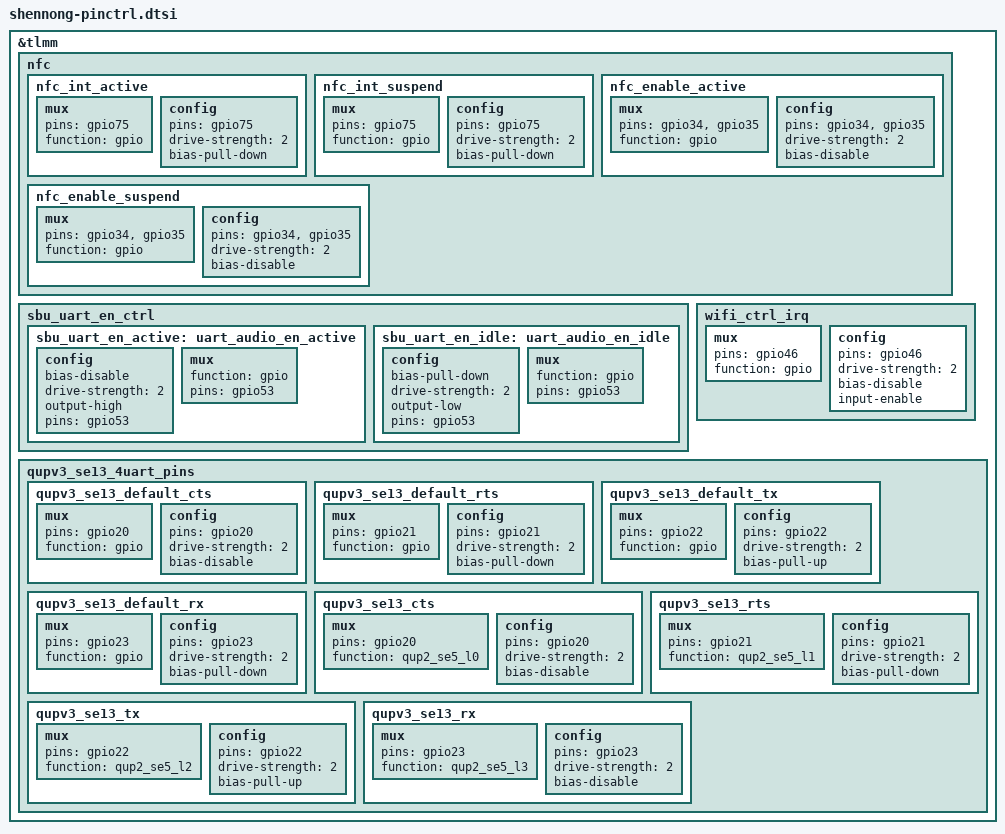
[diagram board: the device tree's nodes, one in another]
/*for shennong pinctrl */
&tlmm {
	nfc {
		nfc_int_active: nfc_int_active {
			/* active state */
			mux {
				/* NFC Read Interrupt */
				pins = "gpio75";
				function = "gpio";
			};

			config {
				pins = "gpio75";
				drive-strength = <2>; /* 2 MA */
				bias-pull-down;
			};
		};

		nfc_int_suspend: nfc_int_suspend {
			/* sleep state */
			mux {
				/* NFC Read Interrupt */
				pins = "gpio75";
				function = "gpio";
			};

			config {
				pins = "gpio75";
				drive-strength = <2>; /* 2 MA */
				bias-pull-down;
			};
		};

		nfc_enable_active: nfc_enable_active {
			mux {
				/* Enable, and Clock request gpios */
				pins = "gpio34", "gpio35";
				function = "gpio";
			};

			config {
				pins = "gpio34", "gpio35";
				drive-strength = <2>; /* 2 MA */
				bias-disable;
			};
		};

		nfc_enable_suspend: nfc_enable_suspend {
			mux {
				pins = "gpio34", "gpio35";
				function = "gpio";
			};

			config {
				pins = "gpio34", "gpio35";
				drive-strength = <2>; /* 2 MA */
				bias-disable;
			};
		};
	}; //nfc

	sbu_uart_en_ctrl {
		sbu_uart_en_active: uart_audio_en_active {
			config {
				bias-disable;
				drive-strength = <2>; /* 2 MA */
				output-high;
				pins = "gpio53";
			};

			mux {
				function = "gpio";
				pins = "gpio53";
			};
		};

		sbu_uart_en_idle: uart_audio_en_idle {
			config {
				bias-pull-down;
				drive-strength = <2>; /* 2 MA */
				output-low;
				pins = "gpio53";
			};

			mux {
				function = "gpio";
				pins = "gpio53";
			};
		};
	};

	wifi_ctrl_irq: wifi_ctrl_irq {
		mux {
			pins = "gpio46";
			function = "gpio";
		};

		config {
			pins = "gpio46";
			drive-strength = <2>;   /* 2 mA */
			bias-disable;
			input-enable;
		};
	}; //wifi

	qupv3_se13_4uart_pins: qupv3_se13_4uart_pins {
		qupv3_se13_default_cts: qupv3_se13_default_cts {
			mux {
				pins = "gpio20";
				function = "gpio";
			};

			config {
				pins = "gpio20";
				drive-strength = <2>;
				bias-disable;
			};
		};

		qupv3_se13_default_rts: qupv3_se13_default_rts {
			mux {
				pins = "gpio21";
				function = "gpio";
			};

			config {
				pins = "gpio21";
				drive-strength = <2>;
				bias-pull-down;
			};
		};

		qupv3_se13_default_tx: qupv3_se13_default_tx {
			mux {
				pins = "gpio22";
				function = "gpio";
			};

			config {
				pins = "gpio22";
				drive-strength = <2>;
				bias-pull-up;
			};
		};

		qupv3_se13_default_rx: qupv3_se13_default_rx {
			mux {
				pins = "gpio23";
				function = "gpio";
			};

			config {
				pins = "gpio23";
				drive-strength = <2>;
				bias-pull-down;
			};
		};

		qupv3_se13_cts: qupv3_se13_cts {
			mux {
				pins = "gpio20";
				function = "qup2_se5_l0";
			};

			config {
				pins = "gpio20";
				drive-strength = <2>;
				bias-disable;
			};
		};

		qupv3_se13_rts: qupv3_se13_rts {
			mux {
				pins = "gpio21";
				function = "qup2_se5_l1";
			};

			config {
				pins = "gpio21";
				drive-strength = <2>;
				bias-pull-down;
			};
		};

		qupv3_se13_tx: qupv3_se13_tx {
			mux {
				pins = "gpio22";
				function = "qup2_se5_l2";
			};

			config {
				pins = "gpio22";
				drive-strength = <2>;
				bias-pull-up;
			};
		};

		qupv3_se13_rx: qupv3_se13_rx {
			mux {
				pins = "gpio23";
				function = "qup2_se5_l3";
			};

			config {
				pins = "gpio23";
				drive-strength = <2>;
				bias-disable;
			};
		};
	}; // satellite UART
}; //tlmm
